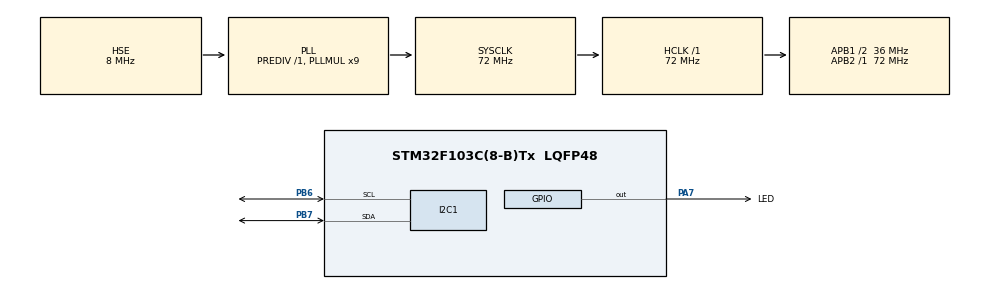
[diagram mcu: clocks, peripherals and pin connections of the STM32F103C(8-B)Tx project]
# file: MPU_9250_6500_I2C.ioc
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Mcu.Family=STM32F1
Mcu.Name=STM32F103C(8-B)Tx
Mcu.Package=LQFP48
NVIC.PriorityGroup=NVIC_PRIORITYGROUP_4
PA13.Mode=Serial_Wire
PA13.Signal=SYS_JTMS-SWDIO
PA14.Mode=Serial_Wire
PA14.Signal=SYS_JTCK-SWCLK
PA7.GPIO_Label=LED
PA7.PinState=GPIO_PIN_SET
PA7.Signal=GPIO_Output
PB6.Mode=I2C
PB6.Signal=I2C1_SCL
PB7.Mode=I2C
PB7.Signal=I2C1_SDA
PD0-OSC_IN.Mode=HSE-External-Oscillator
PD0-OSC_IN.Signal=RCC_OSC_IN
PD1-OSC_OUT.Mode=HSE-External-Oscillator
PD1-OSC_OUT.Signal=RCC_OSC_OUT
ProjectManager.HeapSize=0x200
ProjectManager.StackSize=0x400
ProjectManager.TargetToolchain=STM32CubeIDE
RCC.AHBFreq_Value=72000000
RCC.APB1CLKDivider=RCC_HCLK_DIV2
RCC.APB1Freq_Value=36000000
RCC.APB1TimFreq_Value=72000000
RCC.APB2Freq_Value=72000000
RCC.APB2TimFreq_Value=72000000
RCC.HCLKFreq_Value=72000000
RCC.PLLMUL=RCC_PLL_MUL9
RCC.PLLSourceVirtual=RCC_PLLSOURCE_HSE
RCC.SYSCLKFreq_VALUE=72000000
RCC.SYSCLKSource=RCC_SYSCLKSOURCE_PLLCLK
RCC.USBFreq_Value=72000000
board=custom

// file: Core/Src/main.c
/* USER CODE BEGIN Header */
/**
  ******************************************************************************
  * @file           : main.c
  * @brief          : Main program body
  ******************************************************************************
  * @attention
  *
  * Copyright (c) 2025 STMicroelectronics.
  * All rights reserved.
  *
  * This software is licensed under terms that can be found in the LICENSE file
  * in the root directory of this software component.
  * If no LICENSE file comes with this software, it is provided AS-IS.
  *
  ******************************************************************************
  */
/* USER CODE END Header */
#include "main.h"

/* USER CODE BEGIN Includes */
#include <stdio.h>
#include "mpu9255.h"
/* USER CODE END Includes */

/* USER CODE BEGIN PTD */
typedef struct {
    int16_t accel[3];  // X,Y,Z (m/s² × 100)
    int16_t gyro[3];   // X,Y,Z (°/s × 100)
    int16_t mag[3];    // X,Y,Z (μT × 10)
    uint32_t timestamp; // ms since startup
} SensorData;
/* USER CODE END PTD */

/* USER CODE BEGIN PD */
// Configuration
#define SAMPLE_RATE_HZ   100     // 100Hz sampling
#define BUFFER_SIZE      200     // 2 seconds of data (200 samples)
#define DURATION_SEC     10      // 10 seconds of recording
#define TOTAL_SAMPLES    (SAMPLE_RATE_HZ * DURATION_SEC)
/* USER CODE END PD */

I2C_HandleTypeDef hi2c1;
MPU9255_t IMU_Data;

// Circular buffer
SensorData sensorBuffer[BUFFER_SIZE];
volatile uint16_t bufferHead = 0;  // Write position
volatile uint16_t bufferTail = 0;  // Read position
volatile uint8_t bufferFull = 0;

void SystemClock_Config(void);
static void MX_GPIO_Init(void);
static void MX_I2C1_Init(void);

/* USER CODE BEGIN PFP */
void storeSensorData(void);
/* USER CODE END PFP */

int main(void)
{

  /* MCU Configuration--------------------------------------------------------*/

  /* Reset of all peripherals, Initializes the Flash interface and the Systick. */
  HAL_Init();

  /* Configure the system clock */
  SystemClock_Config();

  /* USER CODE BEGIN SysInit */
  if (!MPU9255_Init(&hi2c1)) {
          // Blink LED fast if init fails
          while(1) {
              HAL_GPIO_TogglePin(LED_GPIO_Port, LED_Pin);
              HAL_Delay(100);
          }
      }

  /* USER CODE END SysInit */

  /* Initialize all configured peripherals */
  MX_GPIO_Init();
  MX_I2C1_Init();
  /* USER CODE BEGIN 2 */

  // Main data collection loop
  uint32_t lastTick = HAL_GetTick();
  /* USER CODE END 2 */

  /* Infinite loop */
  /* USER CODE BEGIN WHILE */
  while (1) {
          /* USER CODE BEGIN 3 */
          readAll(&hi2c1, &IMU_Data);
          storeSensorData();

          // Toggle LED every 100ms (visual feedback)
          static uint32_t lastToggle = 0;
          if (HAL_GetTick() - lastToggle > 100) {
              HAL_GPIO_TogglePin(LED_GPIO_Port, LED_Pin);
              lastToggle = HAL_GetTick();
          }

          // Precise 100Hz timing
          while ((HAL_GetTick() - lastTick) < (1000/SAMPLE_RATE_HZ)) { __NOP(); }
          lastTick = HAL_GetTick();
      }
  /* USER CODE END 3 */
}

void SystemClock_Config(void)
{
  RCC_OscInitTypeDef RCC_OscInitStruct = {0};
  RCC_ClkInitTypeDef RCC_ClkInitStruct = {0};

  /** Initializes the RCC Oscillators according to the specified parameters
  * in the RCC_OscInitTypeDef structure.
  */
  RCC_OscInitStruct.OscillatorType = RCC_OSCILLATORTYPE_HSE;
  RCC_OscInitStruct.HSEState = RCC_HSE_ON;
  RCC_OscInitStruct.HSEPredivValue = RCC_HSE_PREDIV_DIV1;
  RCC_OscInitStruct.HSIState = RCC_HSI_ON;
  RCC_OscInitStruct.PLL.PLLState = RCC_PLL_ON;
  RCC_OscInitStruct.PLL.PLLSource = RCC_PLLSOURCE_HSE;
  RCC_OscInitStruct.PLL.PLLMUL = RCC_PLL_MUL9;
  if (HAL_RCC_OscConfig(&RCC_OscInitStruct) != HAL_OK)
  {
    Error_Handler();
  }

  /** Initializes the CPU, AHB and APB buses clocks
  */
  RCC_ClkInitStruct.ClockType = RCC_CLOCKTYPE_HCLK|RCC_CLOCKTYPE_SYSCLK
                              |RCC_CLOCKTYPE_PCLK1|RCC_CLOCKTYPE_PCLK2;
  RCC_ClkInitStruct.SYSCLKSource = RCC_SYSCLKSOURCE_PLLCLK;
  RCC_ClkInitStruct.AHBCLKDivider = RCC_SYSCLK_DIV1;
  RCC_ClkInitStruct.APB1CLKDivider = RCC_HCLK_DIV2;
  RCC_ClkInitStruct.APB2CLKDivider = RCC_HCLK_DIV1;

  if (HAL_RCC_ClockConfig(&RCC_ClkInitStruct, FLASH_LATENCY_2) != HAL_OK)
  {
    Error_Handler();
  }
}

static void MX_I2C1_Init(void)
{

  hi2c1.Instance = I2C1;
  hi2c1.Init.ClockSpeed = 100000;
  hi2c1.Init.DutyCycle = I2C_DUTYCYCLE_2;
  hi2c1.Init.OwnAddress1 = 0;
  hi2c1.Init.AddressingMode = I2C_ADDRESSINGMODE_7BIT;
  hi2c1.Init.DualAddressMode = I2C_DUALADDRESS_DISABLE;
  hi2c1.Init.OwnAddress2 = 0;
  hi2c1.Init.GeneralCallMode = I2C_GENERALCALL_DISABLE;
  hi2c1.Init.NoStretchMode = I2C_NOSTRETCH_DISABLE;
  if (HAL_I2C_Init(&hi2c1) != HAL_OK)
  {
    Error_Handler();
  }

}

static void MX_GPIO_Init(void)
{
  GPIO_InitTypeDef GPIO_InitStruct = {0};

  /* GPIO Ports Clock Enable */
  __HAL_RCC_GPIOD_CLK_ENABLE();
  __HAL_RCC_GPIOA_CLK_ENABLE();
  __HAL_RCC_GPIOB_CLK_ENABLE();

  /*Configure GPIO pin Output Level */
  HAL_GPIO_WritePin(LED_GPIO_Port, LED_Pin, GPIO_PIN_SET);

  /*Configure GPIO pin : LED_Pin */
  GPIO_InitStruct.Pin = LED_Pin;
  GPIO_InitStruct.Mode = GPIO_MODE_OUTPUT_PP;
  GPIO_InitStruct.Pull = GPIO_NOPULL;
  GPIO_InitStruct.Speed = GPIO_SPEED_FREQ_LOW;
  HAL_GPIO_Init(LED_GPIO_Port, &GPIO_InitStruct);

}

/* USER CODE BEGIN 4 */
void storeSensorData(void) {
    // Store scaled integer values
    sensorBuffer[bufferHead].accel[0] = (int16_t)(IMU_Data.AccelX * 100); // 0.01 m/s² resolution
    sensorBuffer[bufferHead].accel[1] = (int16_t)(IMU_Data.AccelY * 100);
    sensorBuffer[bufferHead].accel[2] = (int16_t)(IMU_Data.AccelZ * 100);

    sensorBuffer[bufferHead].gyro[0] = (int16_t)(IMU_Data.GyroX * 100);   // 0.01 °/s resolution
    sensorBuffer[bufferHead].gyro[1] = (int16_t)(IMU_Data.GyroY * 100);
    sensorBuffer[bufferHead].gyro[2] = (int16_t)(IMU_Data.GyroZ * 100);

    sensorBuffer[bufferHead].mag[0] = (int16_t)(IMU_Data.MagX * 10);      // 0.1 μT resolution
    sensorBuffer[bufferHead].mag[1] = (int16_t)(IMU_Data.MagY * 10);
    sensorBuffer[bufferHead].mag[2] = (int16_t)(IMU_Data.MagZ * 10);

    sensorBuffer[bufferHead].timestamp = HAL_GetTick();

    // Advance head pointer
    bufferHead = (bufferHead + 1) % BUFFER_SIZE;

    // Handle buffer full condition
    if (bufferHead == bufferTail) {
        bufferFull = 1;
        bufferTail = (bufferTail + 1) % BUFFER_SIZE; // Overwrite oldest data
    }
}
/* USER CODE END 4 */

void Error_Handler(void)
{
  __disable_irq();
  while (1)
  {
  }
}
